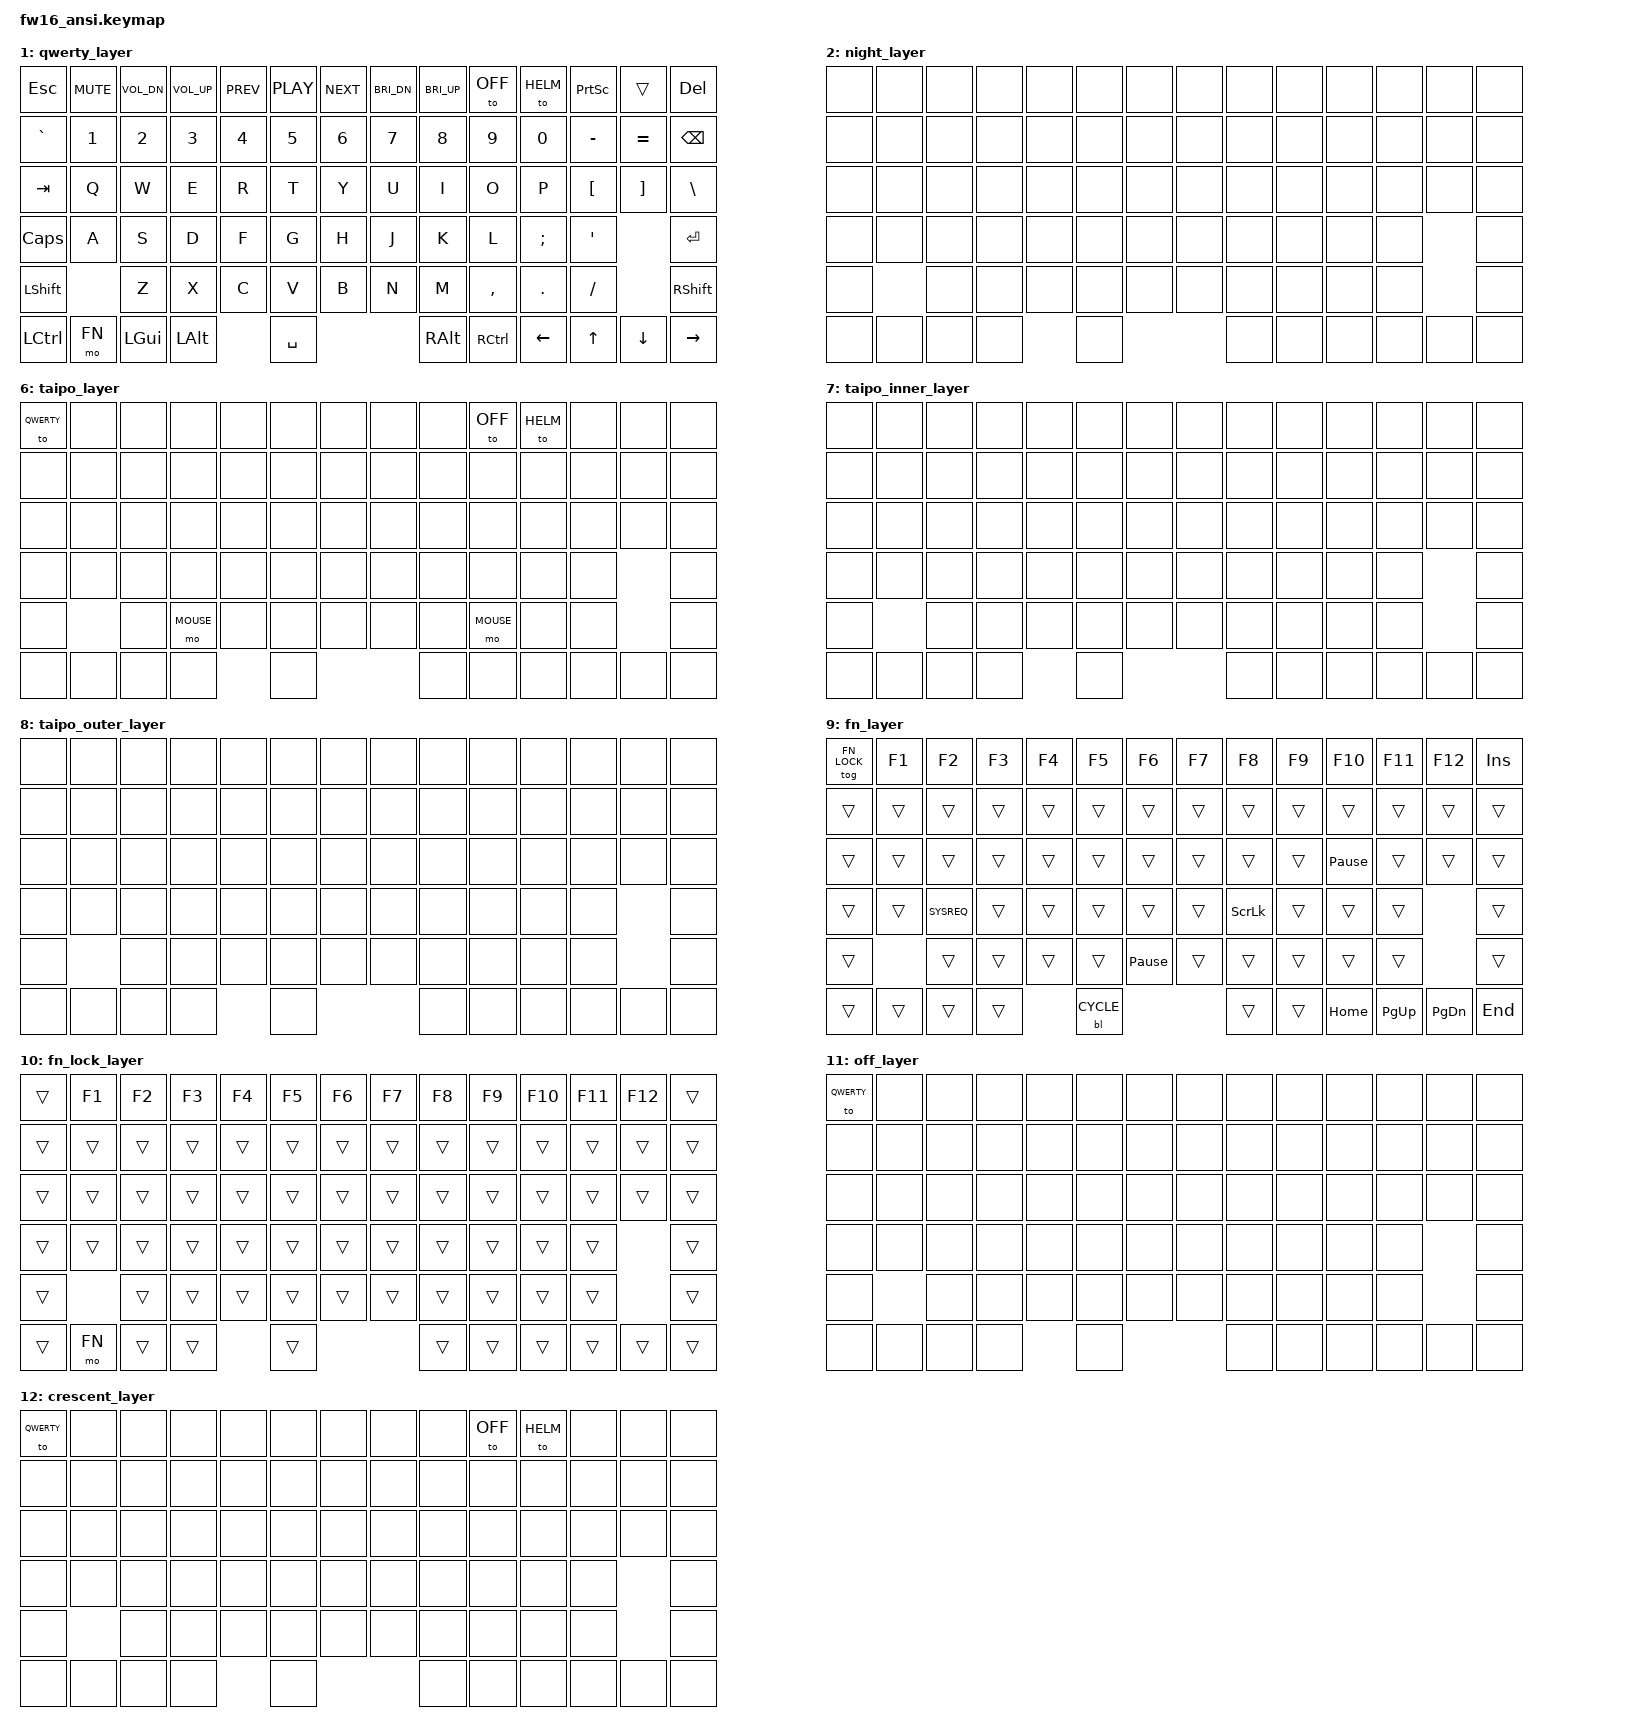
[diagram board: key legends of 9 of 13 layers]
#include <behaviors.dtsi>
#include <dt-bindings/zmk/keys.h>
#include <dt-bindings/zmk/backlight.h>
#include "./key-labels/fw16.h"

// Define before base
#define CRESCENT 12

#include "base.keymap"

#define FN 9
#define FN_LOCK 10
#define OFF 11


ZMK_LAYER(helm_layer,
  &to QWERTY    &kp C_MUTE    &kp C_VOL_DN  &kp C_VOL_UP  &kp C_PREV    &kp C_PLAY    &kp C_NEXT    &kp C_BRI_DN  &kp C_BRI_UP  &to OFF       &none         &none         &to TAIPO     &none
  &none         &none         &none         &none         &none         &none         &none         &none         &none         &none         &none         &none         &none         &none
  &none         LEFT_HELM_UPPER_ROW________________________________________________   RIGHT_HELM_UPPER_ROW_______________________________________________   &none         &none         &none
  &none         LEFT_HELM_MIDDLE_ROW_______________________________________________   RIGHT_HELM_MIDDLE_ROW______________________________________________   &none                       &none
  &none                       LEFT_HELM_LOWER_ROW____________________   L_THUMB       &none         R_THUMB       RIGHT_HELM_LOWER_ROW___________________   &none                       &none
  &none         &none         &none         &none                       &none                                     &none         &none         &none         &none         &none         &none
)

ZMK_LAYER(qwerty_layer,
  &kp ESC       &kp C_MUTE    &kp C_VOL_DN  &kp C_VOL_UP  &kp C_PREV    &kp C_PLAY    &kp C_NEXT    &kp C_BRI_DN  &kp C_BRI_UP  &to OFF       &to HELM      &kp PSCRN     &trans        &kp DEL
  &kp GRAVE     &kp N1        &kp N2        &kp N3        &kp N4        &kp N5        &kp N6        &kp N7        &kp N8        &kp N9        &kp N0        &kp MINUS     &kp EQUAL     &kp BSPC
  &kp TAB       &kp Q         &kp W         &kp E         &kp R         &kp T         &kp Y         &kp U         &kp I         &kp O         &kp P         &kp LBKT      &kp RBKT      &kp BSLH
  &kp CAPSLOCK  &kp A         &kp S         &kp D         &kp F         &kp G         &kp H         &kp J         &kp K         &kp L         &kp SEMI      &kp SQT                     &kp ENTER
  &kp LSHFT                   &kp Z         &kp X         &kp C         &kp V         &kp B         &kp N         &kp M         &kp COMMA     &kp DOT       &kp SLASH                   &kp RSHFT
  &kp LCTRL     &mo FN        &kp LGUI      &kp LALT                    &kp SPACE                                 &kp RALT      &kp RCTRL     &kp LEFT      &kp UP        &kp DOWN      &kp RIGHT
)

ZMK_LAYER(night_layer,
  &none         &none         &none         &none         &none         &none         &none         &none         &none         &none         &none         &none         &none         &none
  &none         &none         &none         &none         &none         &none         &none         &none         &none         &none         &none         &none         &none         &none
  &none         &none         &none         &none         &none         &none         &none         &none         &none         &none         &none         &none         &none         &none
  &none         &none         &none         &none         &none         &none         &none         &none         &none         &none         &none         &none                       &none
  &none                       &none         &none         &none         &none         &none         &none         &none         &none         &none         &none                       &none
  &none         &none         &none         &none                       &none                                     &none         &none         &none         &none         &none         &none
)

ZMK_LAYER(port_layer,
   &none         &none         &none         &none         &none         &none         &none         &none         &none         &none         &none         &none         &none         &none
  &none         &none         &none         &none         &none         &none         &none         &none         &none         &none         &none         &none         &none         &none
  &none         LEFT_PORT_UPPER_ROW________________________________________________   RIGHT_PORT_UPPER_ROW_______________________________________________   &none         &none         &none
  &none         LEFT_PORT_MIDDLE_ROW_______________________________________________   RIGHT_PORT_MIDDLE_ROW______________________________________________   &none                       &none
  &none                       LEFT_PORT_LOWER_ROW____________________   L_THUMB       &none         R_THUMB       RIGHT_PORT_LOWER_ROW___________________   &none                       &none
  &none         &none         &none         &none                       &none                                     &none         &none         &none         &none         &none         &none
)

ZMK_LAYER(starboard_layer,
  &none         &none         &none         &none         &none         &none         &none         &none         &none         &none         &none         &none         &none         &none
  &none         &none         &none         &none         &none         &none         &none         &none         &none         &none         &none         &none         &none         &none
  &none         LEFT_STARBOARD_UPPER_ROW___________________________________________   RIGHT_STARBOARD_UPPER_ROW__________________________________________   &none         &none         &none
  &none         LEFT_STARBOARD_MIDDLE_ROW__________________________________________   RIGHT_STARBOARD_MIDDLE_ROW_________________________________________   &none                       &none
  &none                       LEFT_STARBOARD_LOWER_ROW_______________   L_THUMB       &none         R_THUMB       RIGHT_STARBOARD_LOWER_ROW______________   &none                       &none
  &none         &none         &none         &none                       &none                                     &none         &none         &none         &none         &none         &none
)

ZMK_LAYER(aft_layer,
  &none         &none         &none         &none         &none         &none         &none         &none         &none         &none         &none         &to CRESCENT  &none         &none
  &none         &none         &none         &none         &none         &none         &none         &none         &none         &none         &none         &none         &none         &none
  &none         LEFT_AFT_UPPER_ROW_________________________________________________   RIGHT_AFT_UPPER_ROW________________________________________________   &none         &none         &none
  &none         LEFT_AFT_MIDDLE_ROW________________________________________________   RIGHT_AFT_MIDDLE_ROW_______________________________________________   &none                       &none
  &none                       LEFT_AFT_LOWER_ROW_____________________   L_THUMB       &none         R_THUMB       RIGHT_AFT_LOWER_ROW____________________   &none                       &none
  &none         &none         &none         &none                       &none                                     &none         &none         &none         &none         &none         &none
)

ZMK_LAYER(taipo_layer,
  &to QWERTY    &none         &none         &none         &none         &none         &none         &none         &none         &to OFF       &to HELM      &none         &none         &none
  &none         &none         &none         &none         &none         &none         &none         &none         &none         &none         &none         &none         &none         &none
  &none         &none         &none         &none         &none         &none         &none         &none         &none         &none         &none         &none         &none         &none
  &none         &none         &none         &none         &none         &none         &none         &none         &none         &none         &none         &none                       &none
  &none                       &none         &mo MOUSE     &none         &none         &none         &none         &none         &mo MOUSE     &none         &none                       &none
  &none         &none         &none         &none                       &none                                     &none         &none         &none         &none         &none         &none
)
ZMK_COMBO(Lmouse, &mo MOUSE, ITL OTL, TAIPO, COMBO_TERM_FAST)
ZMK_COMBO(Rmouse, &mo MOUSE, ITR OTR, TAIPO, COMBO_TERM_FAST)
ZMK_COMBO(Bmouse, &mo MOUSE, ITL ITR, TAIPO, COMBO_TERM_FAST)

ZMK_LAYER(taipo_inner_layer,
  &none         &none         &none         &none         &none         &none         &none         &none         &none         &none         &none         &none         &none         &none
  &none         &none         &none         &none         &none         &none         &none         &none         &none         &none         &none         &none         &none         &none
  &none         &none         &none         &none         &none         &none         &none         &none         &none         &none         &none         &none         &none         &none
  &none         &none         &none         &none         &none         &none         &none         &none         &none         &none         &none         &none                       &none
  &none                       &none         &none         &none         &none         &none         &none         &none         &none         &none         &none                       &none
  &none         &none         &none         &none                       &none                                     &none         &none         &none         &none         &none         &none
)

ZMK_LAYER(taipo_outer_layer,
  &none         &none         &none         &none         &none         &none         &none         &none         &none         &none         &none         &none         &none         &none
  &none         &none         &none         &none         &none         &none         &none         &none         &none         &none         &none         &none         &none         &none
  &none         &none         &none         &none         &none         &none         &none         &none         &none         &none         &none         &none         &none         &none
  &none         &none         &none         &none         &none         &none         &none         &none         &none         &none         &none         &none                       &none
  &none                       &none         &none         &none         &none         &none         &none         &none         &none         &none         &none                       &none
  &none         &none         &none         &none                       &none                                     &none         &none         &none         &none         &none         &none
)

ZMK_LAYER(fn_layer,
  &tog FN_LOCK    &kp F1    &kp F2        &kp F3        &kp F4        &kp F5        &kp F6        &kp F7    &kp F8        &kp F9        &kp F10       &kp F11       &kp F12       &kp INS
  &trans          &trans    &trans        &trans        &trans        &trans        &trans        &trans    &trans        &trans        &trans        &trans        &trans        &trans
  &trans          &trans    &trans        &trans        &trans        &trans        &trans        &trans    &trans        &trans        &kp PAUSE_BREAK &trans      &trans        &trans
  &trans          &trans    &kp SYSREQ    &trans        &trans        &trans        &trans        &trans    &kp SLCK      &trans        &trans        &trans        &trans
  &trans          &trans    &trans        &trans        &trans        &kp PAUSE_BREAK &trans      &trans    &trans        &trans        &trans        &trans
  &trans          &trans    &trans        &trans        &bl BL_CYCLE  &trans        &trans        &kp HOME  &kp PG_UP     &kp PG_DN     &kp END
)

ZMK_LAYER(fn_lock_layer,
  &trans    &kp F1    &kp F2    &kp F3    &kp F4    &kp F5    &kp F6    &kp F7    &kp F8    &kp F9    &kp F10   &kp F11   &kp F12   &trans
  &trans    &trans    &trans    &trans    &trans    &trans    &trans    &trans    &trans    &trans    &trans    &trans    &trans    &trans
  &trans    &trans    &trans    &trans    &trans    &trans    &trans    &trans    &trans    &trans    &trans    &trans    &trans    &trans
  &trans    &trans    &trans    &trans    &trans    &trans    &trans    &trans    &trans    &trans    &trans    &trans                &trans
  &trans    &trans    &trans    &trans    &trans    &trans    &trans    &trans    &trans    &trans    &trans    &trans
  &trans    &mo FN    &trans    &trans    &trans    &trans    &trans    &trans    &trans    &trans    &trans
)

ZMK_LAYER(off_layer,
  &to QWERTY    &none         &none         &none         &none         &none         &none         &none         &none         &none         &none         &none         &none         &none
  &none         &none         &none         &none         &none         &none         &none         &none         &none         &none         &none         &none         &none         &none
  &none         &none         &none         &none         &none         &none         &none         &none         &none         &none         &none         &none         &none         &none
  &none         &none         &none         &none         &none         &none         &none         &none         &none         &none         &none         &none                       &none
  &none                       &none         &none         &none         &none         &none         &none         &none         &none         &none         &none                       &none
  &none         &none         &none         &none                       &none                                     &none         &none         &none         &none         &none         &none
)

ZMK_LAYER(crescent_layer,
  &to QWERTY    &none         &none         &none         &none         &none         &none         &none         &none         &to OFF       &to HELM      &none         &none         &none
  &none         &none         &none         &none         &none         &none         &none         &none         &none         &none         &none         &none         &none         &none
  &none         &none         &none         &none         &none         &none         &none         &none         &none         &none         &none         &none         &none         &none
  &none         &none         &none         &none         &none         &none         &none         &none         &none         &none         &none         &none                       &none
  &none                       &none         &none         &none         &none         &none         &none         &none         &none         &none         &none                       &none
  &none         &none         &none         &none                       &none                                     &none         &none         &none         &none         &none         &none
)
